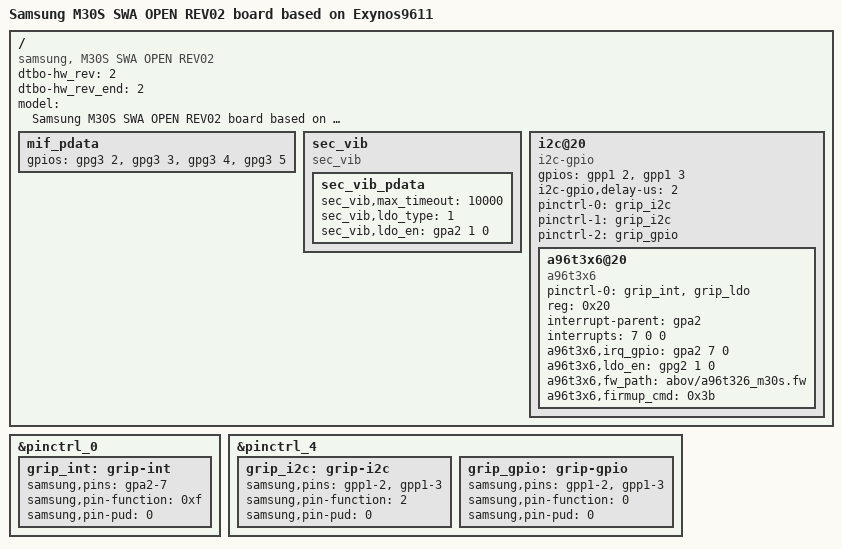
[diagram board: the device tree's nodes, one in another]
/*
 * SAMSUNG EXYNOS9610 board device tree source
 *
 * Copyright (c) 2018 Samsung Electronics Co., Ltd.
 *		http://www.samsung.com
 *
 * This program is free software; you can redistribute it and/or modify
 * it under the terms of the GNU General Public License version 2 as
 * published by the Free Software Foundation.
 */

/dts-v1/;
/plugin/;
#include "exynos9611-m30s_common.dtsi"
#include "exynos9611-m30s_fingerprint_00.dtsi"
#include "exynos9611-m30s_sensorhub_00.dtsi"
#include "exynos9610-a50_nfc_01.dtsi"
#include "exynos9611-m30s_swa_open_gpio_02.dtsi"

/ {
	compatible = "samsung, M30S SWA OPEN REV02", "samsung,EXYNOS9611";
	dtbo-hw_rev = <2>;
	dtbo-hw_rev_end = <2>;

	fragment@model {
		target-path = "/";
		__overlay__ {
			#address-cells = <2>;
			#size-cells = <1>;

			model = "Samsung M30S SWA OPEN REV02 board based on Exynos9611";

			mif_pdata {
				/* GPIOs for HW REV */
				/* XGPIO26-AP_REV0, XGPIO27-AP_REV1, XGPIO28-AP_REV2, XGPIO29-AP_REV3 */
				gpios = <&gpg3 2 0>, <&gpg3 3 0>, <&gpg3 4 0>, <&gpg3 5 0>;
				pinctrl-names = "default";
			};

			sec_vib {
				compatible = "sec_vib";
				sec_vib_pdata {
					status = "okay";
					sec_vib,max_timeout = <10000>;
					sec_vib,ldo_type = <1>;
					sec_vib,ldo_en = <&gpa2 1 0>;
				};
			};
			i2c@20 {
				compatible = "i2c-gpio";
				gpios = <&gpp1 2 0
						&gpp1 3 0>;
				i2c-gpio,delay-us = <2>;
				pinctrl-names = "default","on_i2c","off_i2c";
				pinctrl-0 = <&grip_i2c>;
				pinctrl-1 = <&grip_i2c>;
				pinctrl-2 = <&grip_gpio>;

				a96t3x6@20 {
					compatible = "a96t3x6";
					pinctrl-names = "default";
					pinctrl-0 = <&grip_int &grip_ldo>;
					reg = <0x20>;
					interrupt-parent = <&gpa2>;
					interrupts = <7 0 0>;
					a96t3x6,irq_gpio = <&gpa2 7 0>;
					a96t3x6,ldo_en = <&gpg2 1 0>;
					a96t3x6,fw_path = "abov/a96t326_m30s.fw";
					a96t3x6,firmup_cmd = <0x3b>;
				};
			};

		}; /* end of __overlay__ */
	}; /* end of fragment */
}; /* end of root */

&pinctrl_0 {
	grip_int: grip-int {
		samsung,pins = "gpa2-7";
		samsung,pin-function = <0xf>;
		samsung,pin-pud = <0>;
	};	
};

&pinctrl_4 {
	grip_i2c: grip-i2c {
		samsung,pins = "gpp1-2", "gpp1-3";
		samsung,pin-function = <2>;
		samsung,pin-pud = <0>;
	};

	grip_gpio: grip-gpio {
		samsung,pins = "gpp1-2", "gpp1-3";
		samsung,pin-function = <0>;
		samsung,pin-pud = <0>;
	};
};
